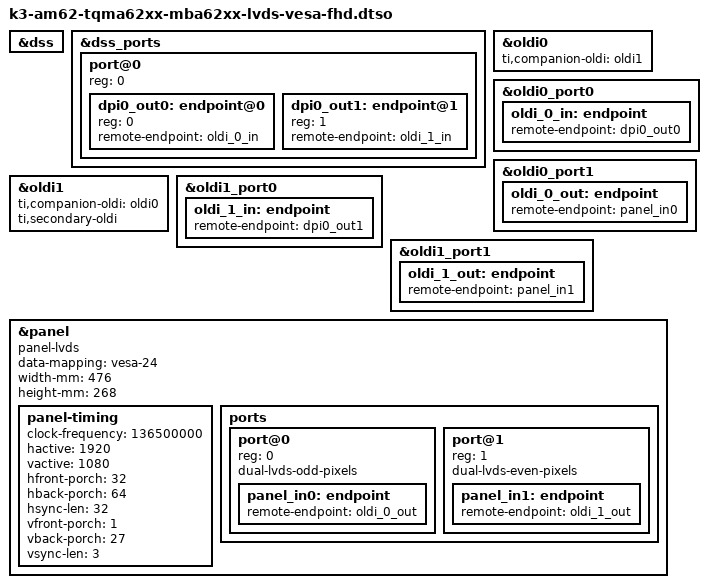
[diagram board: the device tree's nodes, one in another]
// SPDX-License-Identifier: GPL-2.0-only OR MIT
/*
 * Copyright (c) 2023-2026 TQ-Systems GmbH <linux@ew.tq-group.com>, D-82229 Seefeld, Germany.
 * Author: Nora Schiffer
 */

/dts-v1/;
/plugin/;

&dss {
	status = "okay";
};

&dss_ports {
	#address-cells = <1>;
	#size-cells = <0>;

	/* VP1: Output to OLDI */
	port@0 {
		reg = <0>;
		#address-cells = <1>;
		#size-cells = <0>;

		dpi0_out0: endpoint@0 {
			reg = <0>;
			remote-endpoint = <&oldi_0_in>;
		};

		dpi0_out1: endpoint@1 {
			reg = <1>;
			remote-endpoint = <&oldi_1_in>;
		};
	};
};

&oldi0 {
	ti,companion-oldi = <&oldi1>;
	status = "okay";
};

/* Mainline labels oldi0/oldi1's ports individually (oldiN_port0/1), not as combined containers. */
&oldi0_port0 {
	oldi_0_in: endpoint {
		remote-endpoint = <&dpi0_out0>;
	};
};

&oldi0_port1 {
	oldi_0_out: endpoint {
		remote-endpoint = <&panel_in0>;
	};
};

&oldi1 {
	ti,companion-oldi = <&oldi0>;
	ti,secondary-oldi;
	status = "okay";
};

&oldi1_port0 {
	oldi_1_in: endpoint {
		remote-endpoint = <&dpi0_out1>;
	};
};

&oldi1_port1 {
	oldi_1_out: endpoint {
		remote-endpoint = <&panel_in1>;
	};
};

&panel {
	compatible = "panel-lvds";
	data-mapping = "vesa-24";
	width-mm = <476>;
	height-mm = <268>;
	status = "okay";

	panel-timing {
		/* 1920x1080@60Hz VESA Reduced Blanking */
		clock-frequency = <136500000>;
		hactive = <1920>;
		vactive = <1080>;
		hfront-porch = <32>;
		hback-porch = <64>;
		hsync-len = <32>;
		vfront-porch = <1>;
		vback-porch = <27>;
		vsync-len = <3>;
	};

	ports {
		#address-cells = <1>;
		#size-cells = <0>;

		port@0 {
			reg = <0>;
			dual-lvds-odd-pixels;

			panel_in0: endpoint {
				remote-endpoint = <&oldi_0_out>;
			};
		};

		port@1 {
			reg = <1>;
			dual-lvds-even-pixels;

			panel_in1: endpoint {
				remote-endpoint = <&oldi_1_out>;
			};
		};
	};
};
